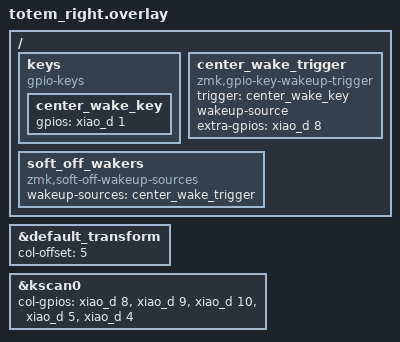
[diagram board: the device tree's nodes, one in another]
#include "totem.dtsi"

&default_transform {
    col-offset = <5>;
};

&kscan0 {
    col-gpios
        = <&xiao_d 8 GPIO_ACTIVE_HIGH>
        , <&xiao_d 9 GPIO_ACTIVE_HIGH>
        , <&xiao_d 10 GPIO_ACTIVE_HIGH>
        , <&xiao_d 5 GPIO_ACTIVE_HIGH>
        , <&xiao_d 4 GPIO_ACTIVE_HIGH>
        ;
};

/ {
    // Physical H key: row 1 / local column 0 (XIAO D1 / D8).
    // The matrix wake input is armed only during soft off.
    keys {
        compatible = "gpio-keys";
        center_wake_key: center_wake_key {
            gpios = <&xiao_d 1 (GPIO_ACTIVE_HIGH | GPIO_PULL_DOWN)>;
        };
    };

    center_wake_trigger: center_wake_trigger {
        compatible = "zmk,gpio-key-wakeup-trigger";
        trigger = <&center_wake_key>;
        wakeup-source;
        extra-gpios = <&xiao_d 8 GPIO_ACTIVE_HIGH>;
    };

    soft_off_wakers {
        compatible = "zmk,soft-off-wakeup-sources";
        wakeup-sources = <&center_wake_trigger>;
    };
};
